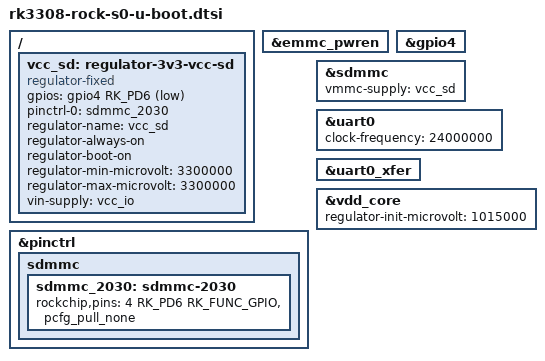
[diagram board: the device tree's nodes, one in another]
// SPDX-License-Identifier: GPL-2.0+

#include "rk3308-u-boot.dtsi"

/ {
	/*
	 * HW revision prior to v1.2 must pull GPIO4_D6 low to access sdmmc.
	 * This is modeled as an always-on active low fixed regulator.
	 */
	vcc_sd: regulator-3v3-vcc-sd {
		compatible = "regulator-fixed";
		gpios = <&gpio4 RK_PD6 GPIO_ACTIVE_LOW>;
		pinctrl-names = "default";
		pinctrl-0 = <&sdmmc_2030>;
		regulator-name = "vcc_sd";
		regulator-always-on;
		regulator-boot-on;
		regulator-min-microvolt = <3300000>;
		regulator-max-microvolt = <3300000>;
		vin-supply = <&vcc_io>;
	};
};

&emmc_pwren {
	bootph-pre-ram;
	bootph-some-ram;
};

&gpio4 {
	bootph-pre-ram;
};

&pinctrl {
	sdmmc {
		sdmmc_2030: sdmmc-2030 {
			rockchip,pins = <4 RK_PD6 RK_FUNC_GPIO &pcfg_pull_none>;
		};
	};
};

&sdmmc {
	vmmc-supply = <&vcc_sd>;
};

&sdmmc_2030 {
	bootph-pre-ram;
};

&uart0 {
	bootph-all;
	clock-frequency = <24000000>;
};

&uart0_xfer {
	bootph-pre-sram;
	bootph-pre-ram;
};

&vcc_sd {
	bootph-pre-ram;
};

&vdd_core {
	regulator-init-microvolt = <1015000>;
};
